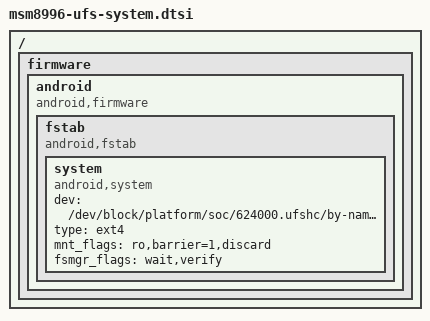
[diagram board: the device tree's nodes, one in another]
//===============================================================
//  ARM: dts: msm: Mount the system partition during early init
//
//  Add support to early mount system partition so that system
//  modules can be loaded during early init for UFS.
//===============================================================

/ {
    firmware: firmware {
        android {
            compatible = "android,firmware";
            fstab {
                compatible = "android,fstab";
                system {
                    compatible = "android,system";
                    dev = "/dev/block/platform/soc/624000.ufshc/by-name/system";
                    type = "ext4";
                    mnt_flags = "ro,barrier=1,discard";
                    fsmgr_flags = "wait,verify";
                    status = "ok";
                };
            };
        };
    };
};
